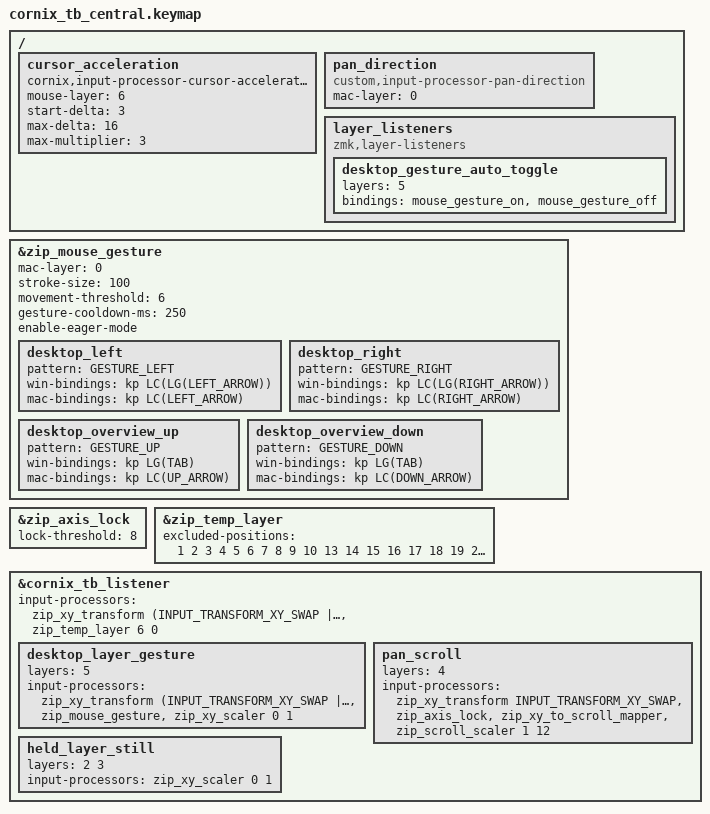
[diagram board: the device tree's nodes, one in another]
/* SPDX-License-Identifier: MIT */
/* The TB-specific editable map is the source of its key layers. */
#include "../../../config/Cornix_tb.keymap"
#include <mouse-gesture.dtsi>

&zip_mouse_gesture {
    mac-layer = <0>;
    stroke-size = <100>;
    movement-threshold = <6>;
    gesture-cooldown-ms = <250>;
    enable-eager-mode;

    desktop_left {
        pattern = <GESTURE_LEFT>;
        win-bindings = <&kp LC(LG(LEFT_ARROW))>;
        mac-bindings = <&kp LC(LEFT_ARROW)>;
    };

    desktop_right {
        pattern = <GESTURE_RIGHT>;
        win-bindings = <&kp LC(LG(RIGHT_ARROW))>;
        mac-bindings = <&kp LC(RIGHT_ARROW)>;
    };

    desktop_overview_up {
        pattern = <GESTURE_UP>;
        win-bindings = <&kp LG(TAB)>;
        mac-bindings = <&kp LC(UP_ARROW)>;
    };

    desktop_overview_down {
        pattern = <GESTURE_DOWN>;
        win-bindings = <&kp LG(TAB)>;
        mac-bindings = <&kp LC(DOWN_ARROW)>;
    };
};

&zip_axis_lock {
    /* Lock promptly after movement starts; retain 1.4x dominance filtering. */
    lock-threshold = <8>;
};

&zip_temp_layer {
    /* Release AML when ESC, Tab, modifiers, or control keys are pressed.
     * Layer keys (30, 31 = BLUETOOTH layer-taps, 42 = BLUETOOTH, 43 = GESTURE,
     * 44 = NUMFN) also release it, so a held layer always wins over AML. */
    excluded-positions = <
        1 2 3 4 5 6 7 8 9 10
        13 14 15 16 17 18 19 20 21 22
        25 26 27 28 29 32 33 34 35 36 37
        41 46 47 48
    >;
};

&cornix_tb_listener {
    /* Sensor is mounted 90 deg from the first guess: swap X/Y; X sign confirmed on hardware, Y not yet. */
    input-processors = <&zip_xy_transform
        (INPUT_TRANSFORM_XY_SWAP | INPUT_TRANSFORM_Y_INVERT)>,
        <&zip_temp_layer 6 0>;

    /* Layer 5 uses desktop gestures, with no pointer output. No axis lock
     * here: its lock threshold and dominance filter swallowed the start of
     * a stroke; the gesture recogniser picks the direction itself. */
    desktop_layer_gesture {
        layers = <5>;
        input-processors = <&zip_xy_transform
            (INPUT_TRANSFORM_XY_SWAP | INPUT_TRANSFORM_Y_INVERT)>,
            <&zip_mouse_gesture>, <&zip_xy_scaler 0 1>;
    };

    pan_scroll {
        layers = <4>;
        input-processors = <&zip_xy_transform INPUT_TRANSFORM_XY_SWAP>,
            <&zip_axis_lock>, <&zip_xy_to_scroll_mapper>,
            <&zip_scroll_scaler 1 12>;
        /* &pan_direction (Mac-only horizontal flip) removed: after the X axis
         * fix the flip made Mac PAN left/right backwards. */
    };

    /* While NUMFN or BLUETOOTH is held the ball does nothing: no cursor
     * motion and no AML (scaled to 0, like the GESTURE layer's pointer). */
    held_layer_still {
        layers = <2 3>;
        input-processors = <&zip_xy_scaler 0 1>;
    };
};

/ {
    cursor_acceleration: cursor_acceleration {
        compatible = "cornix,input-processor-cursor-acceleration";
        #input-processor-cells = <0>;
        mouse-layer = <6>;
        start-delta = <3>;
        max-delta = <16>;
        max-multiplier = <3>;
    };

    pan_direction: pan_direction {
        compatible = "custom,input-processor-pan-direction";
        #input-processor-cells = <0>;
        mac-layer = <0>;
    };

    layer_listeners {
        compatible = "zmk,layer-listeners";
        desktop_gesture_auto_toggle {
            layers = <5>;
            bindings = <&mouse_gesture_on &mouse_gesture_off>;
        };
    };
};
